# ESP32-C3 register map
Vendor: ESPRESSIF SYSTEMS (SHANGHAI) CO., LTD.; Series: ESP32 C-Series; File version: 19
CPU: RV32IMC r0p0, little endian, no MPU, no FPU, 0 interrupt priority bits
Address unit: 32 bits
Registers are 32-bit, read-write, reset 0x0 unless marked. A register's access mark holds for its fields unless they carry their own. Offsets are from the block's base; [hi:lo] are bit positions; lines under a group give offsets from that group; {n}, {i} and the like mark numbered series.

## SYSTIMER — System Timer
Base 0x60023000
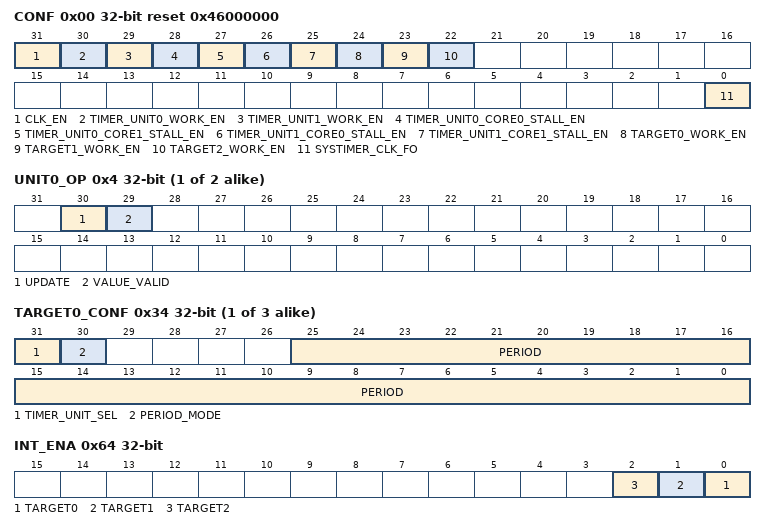
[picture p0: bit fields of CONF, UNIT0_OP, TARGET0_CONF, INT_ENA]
0x00 CONF reset 0x46000000 — SYSTIMER_CONF.
  [31] CLK_EN — register file clk gating
  [30] TIMER_UNIT0_WORK_EN — timer unit0 work enable
  [29] TIMER_UNIT1_WORK_EN — timer unit1 work enable
  [28] TIMER_UNIT0_CORE0_STALL_EN — If timer unit0 is stalled when core0 stalled
  [27] TIMER_UNIT0_CORE1_STALL_EN — If timer unit0 is stalled when core1 stalled
  [26] TIMER_UNIT1_CORE0_STALL_EN — If timer unit1 is stalled when core0 stalled
  [25] TIMER_UNIT1_CORE1_STALL_EN — If timer unit1 is stalled when core1 stalled
  [24] TARGET0_WORK_EN — target0 work enable
  [23] TARGET1_WORK_EN — target1 work enable
  [22] TARGET2_WORK_EN — target2 work enable
  [0] SYSTIMER_CLK_FO — systimer clock force on
{0x4+4i} UNIT{i}_OP (i=0..1) access per field — SYSTIMER_UNIT{i}_OP.
  [30] UPDATE wo — update timer_unit0
  [29] VALUE_VALID ro — reg_timer_unit0_value_valid
{0xC+8i} UNIT{i}LOAD (i=0..1) group — Cluster UNIT{i}LOAD, containing UNIT?_LOAD_HI, UNIT?_LOAD_LO
  0x00 HI — SYSTIMER_UNIT0_LOAD_HI.
    [19:0] LOAD_HI — timer unit0 load high 32 bit
  0x04 LO — SYSTIMER_UNIT0_LOAD_LO.
    [31:0] LOAD_LO — timer unit0 load low 32 bit
{0x1C+8i} TRGT{i} (i=0..2) group — Cluster TRGT{i}, containing TARGET?_HI, TARGET?_LO
  0x00 HI — SYSTIMER_TARGET0_HI.
    [19:0] HI — timer taget0 high 32 bit
  0x04 LO — SYSTIMER_TARGET0_LO.
    [31:0] LO — timer taget0 low 32 bit
{0x34+4i} TARGET{i}_CONF (i=0..2) — SYSTIMER_TARGET{i}_CONF.
  [31] TIMER_UNIT_SEL — select which unit to compare
  [30] PERIOD_MODE — Set target0 to period mode
  [25:0] PERIOD — target0 period
{0x40+8i} UNIT{i}_VALUE (i=0..1) group — Cluster UNIT{i}_VALUE, containing UNIT?_VALUE_HI, UNIT?_VALUE_LO
  0x00 HI ro — SYSTIMER_UNIT0_VALUE_HI.
    [19:0] VALUE_HI — timer read value high 32bit
  0x04 LO ro — SYSTIMER_UNIT0_VALUE_LO.
    [31:0] VALUE_LO — timer read value low 32bit
{0x50+4i} COMP{i}_LOAD (i=0..2) wo — SYSTIMER_COMP{i}_LOAD.
  [0] LOAD — timer comp0 load value
{0x5C+4i} UNIT{i}_LOAD (i=0..1) wo — SYSTIMER_UNIT{i}_LOAD.
  [0] LOAD — timer unit0 load value
0x64 INT_ENA — SYSTIMER_INT_ENA.
  [n] TARGET{n} (n=0..2) — interupt{n} enable
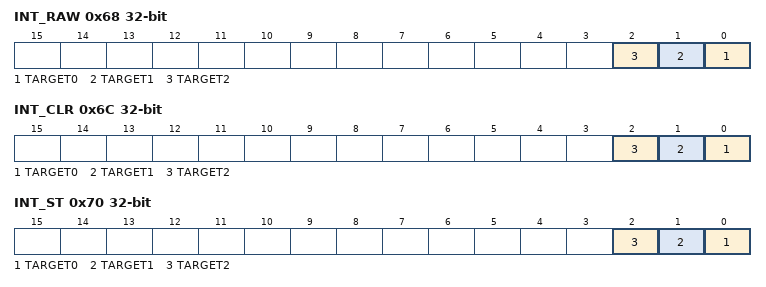
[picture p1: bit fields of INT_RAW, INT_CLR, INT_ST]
0x68 INT_RAW — SYSTIMER_INT_RAW.
  [n] TARGET{n} (n=0..2) — interupt{n} raw
0x6C INT_CLR wo — SYSTIMER_INT_CLR.
  [n] TARGET{n} (n=0..2) write-1-clears — interupt{n} clear
0x70 INT_ST ro — SYSTIMER_INT_ST.
  [n] TARGET{n} (n=0..2) — reg_target{n}_int_st
0xFC DATE — SYSTIMER_DATE.

## TIMG0 — Timer Group 0
Base 0x6001F000
Same registers: TIMG1 0x60020000
{0x0+0x24*i} T{i} (i=0..0) group — Cluster T{i}, containing T?CONFIG, T?LO, T?HI, T?UPDATE, T?ALARMLO, T?ALARMHI, T?LOADLO, T?LOADHI, T?LOAD
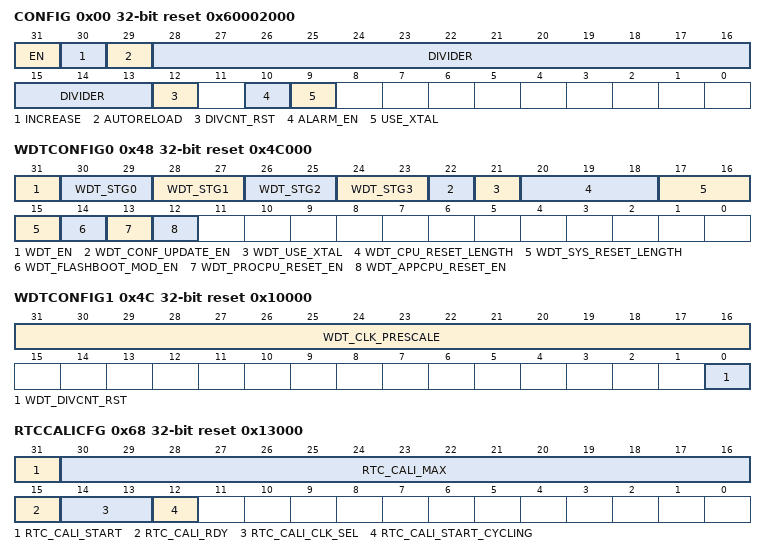
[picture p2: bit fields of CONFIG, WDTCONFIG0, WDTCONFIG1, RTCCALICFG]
  0x00 CONFIG access per field reset 0x60002000 — TIMG_T0CONFIG_REG.
    [31] EN rw — reg_t0_en.
    [30] INCREASE rw — reg_t0_increase.
    [29] AUTORELOAD rw — reg_t0_autoreload.
    [28:13] DIVIDER rw — reg_t0_divider.
    [12] DIVCNT_RST wo — reg_t0_divcnt_rst.
    [10] ALARM_EN rw — reg_t0_alarm_en.
    [9] USE_XTAL rw — reg_t0_use_xtal.
  0x04 LO ro — TIMG_T0LO_REG.
    [31:0] LO — t0_lo
  0x08 HI ro — TIMG_T0HI_REG.
    [21:0] HI — t0_hi
  0x0C UPDATE — TIMG_T0UPDATE_REG.
    [31] UPDATE — t0_update
  0x10 ALARMLO — TIMG_T0ALARMLO_REG.
    [31:0] ALARM_LO — reg_t0_alarm_lo.
  0x14 ALARMHI — TIMG_T0ALARMHI_REG.
    [21:0] ALARM_HI — reg_t0_alarm_hi.
  0x18 LOADLO — TIMG_T0LOADLO_REG.
    [31:0] LOAD_LO — reg_t0_load_lo.
  0x1C LOADHI — TIMG_T0LOADHI_REG.
    [21:0] LOAD_HI — reg_t0_load_hi.
  0x20 LOAD wo — TIMG_T0LOAD_REG.
    [31:0] LOAD — t0_load
0x48 WDTCONFIG0 access per field reset 0x4C000 — TIMG_WDTCONFIG0_REG.
  [31] WDT_EN rw — reg_wdt_en.
  [30-2n:29-2n] WDT_STG{n} rw (n=0..3) — reg_wdt_stg{n}.
  [22] WDT_CONF_UPDATE_EN wo — reg_wdt_conf_update_en.
  [21] WDT_USE_XTAL rw — reg_wdt_use_xtal.
  [20:18] WDT_CPU_RESET_LENGTH rw — reg_wdt_cpu_reset_length.
  [17:15] WDT_SYS_RESET_LENGTH rw — reg_wdt_sys_reset_length.
  [14] WDT_FLASHBOOT_MOD_EN rw — reg_wdt_flashboot_mod_en.
  [13] WDT_PROCPU_RESET_EN rw — reg_wdt_procpu_reset_en.
  [12] WDT_APPCPU_RESET_EN rw — reg_wdt_appcpu_reset_en.
0x4C WDTCONFIG1 access per field reset 0x10000 — TIMG_WDTCONFIG1_REG.
  [31:16] WDT_CLK_PRESCALE rw — reg_wdt_clk_prescale.
  [0] WDT_DIVCNT_RST wo — reg_wdt_divcnt_rst.
{0x48+4i} WDTCONFIG{i} (i=2..5) reset 0x18CBA80 — Watchdog timer stage timeout value
  [31:0] HOLD — reg_wdt_stg0_hold.
0x60 WDTFEED wo — TIMG_WDTFEED_REG.
  [31:0] WDT_FEED
0x64 WDTWPROTECT reset 0x50D83AA1 — TIMG_WDTWPROTECT_REG.
  [31:0] WDT_WKEY — reg_wdt_wkey.
0x68 RTCCALICFG access per field reset 0x13000 — TIMG_RTCCALICFG_REG.
  [31] RTC_CALI_START rw — reg_rtc_cali_start.
  [30:16] RTC_CALI_MAX rw — reg_rtc_cali_max.
  [15] RTC_CALI_RDY ro
  [14:13] RTC_CALI_CLK_SEL rw — reg_rtc_cali_clk_sel.0:rtcslowclock.1:clk_80m.2:xtal_32k
  [12] RTC_CALI_START_CYCLING rw — reg_rtc_cali_start_cycling.
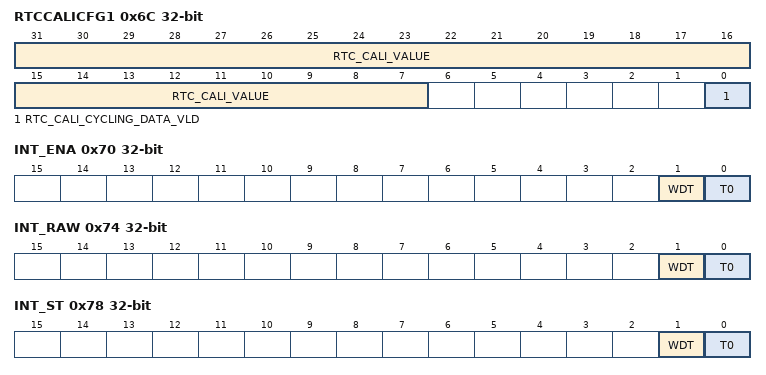
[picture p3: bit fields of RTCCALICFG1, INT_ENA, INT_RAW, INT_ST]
0x6C RTCCALICFG1 ro — TIMG_RTCCALICFG1_REG.
  [31:7] RTC_CALI_VALUE, [0] RTC_CALI_CYCLING_DATA_VLD
0x70 INT_ENA — INT_ENA_TIMG_REG
  [1] WDT — wdt_int_ena
  [n] T{n} (n=0..0) — t{n}_int_ena
0x74 INT_RAW ro — INT_RAW_TIMG_REG
  [1] WDT — wdt_int_raw
  [n] T{n} (n=0..0) — t{n}_int_raw
0x78 INT_ST ro — INT_ST_TIMG_REG
  [1] WDT — wdt_int_st
  [n] T{n} (n=0..0) — t{n}_int_st
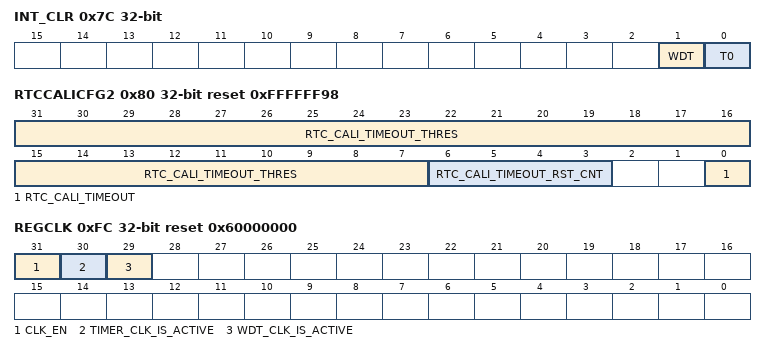
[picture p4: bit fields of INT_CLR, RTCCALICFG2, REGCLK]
0x7C INT_CLR wo — INT_CLR_TIMG_REG
  [1] WDT write-1-clears — wdt_int_clr
  [n] T{n} (n=0..0) write-1-clears — t{n}_int_clr
0x80 RTCCALICFG2 access per field reset 0xFFFFFF98 — TIMG_RTCCALICFG2_REG.
  [31:7] RTC_CALI_TIMEOUT_THRES rw — reg_rtc_cali_timeout_thres.timeoutifcalivaluecountsoverthreshold
  [6:3] RTC_CALI_TIMEOUT_RST_CNT rw — reg_rtc_cali_timeout_rst_cnt.Cyclesthatreleasecalibrationtimeoutreset
  [0] RTC_CALI_TIMEOUT ro — timeoutindicator
0xF8 NTIMG_DATE — TIMG_NTIMG_DATE_REG.
0xFC REGCLK reset 0x60000000 — TIMG_REGCLK_REG.
  [31] CLK_EN — reg_clk_en.
  [30] TIMER_CLK_IS_ACTIVE — reg_timer_clk_is_active.
  [29] WDT_CLK_IS_ACTIVE — reg_wdt_clk_is_active.

## XTS_AES — XTS-AES-128 Flash Encryption
Base 0x600CC000
{0x0+4i} PLAIN_MEM[{i}] (i=0..3) access not given — The memory that stores plaintext
0x40 LINESIZE — XTS-AES line-size register
  [0] LINESIZE — This bit stores the line size parameter. 0: 16Byte, 1: 32Byte.
0x44 DESTINATION — XTS-AES destination register
  [0] DESTINATION — This bit stores the destination. 0: flash(default). 1: reserved.
0x48 PHYSICAL_ADDRESS — XTS-AES physical address register
  [29:0] PHYSICAL_ADDRESS — Those bits stores the physical address. If linesize is 16-byte, the physical address should be aligned of 16 bytes. If linesize is 32-byte, the physical address should be aligned of 32 bytes.
0x4C TRIGGER wo — XTS-AES trigger register
  [0] TRIGGER — Set this bit to start manual encryption calculation
0x50 RELEASE wo — XTS-AES release register
  [0] RELEASE — Set this bit to release the manual encrypted result, after that the result will be visible to spi
0x54 DESTROY wo — XTS-AES destroy register
  [0] DESTROY — Set this bit to destroy XTS-AES result.
0x58 STATE ro — XTS-AES status register
  [1:0] STATE — Those bits shows XTS-AES status. 0=IDLE, 1=WORK, 2=RELEASE, 3=USE. IDLE means that XTS-AES is idle. WORK means that XTS-AES is busy with calculation. RELEASE means the encrypted result is generated but not visible to mspi. USE means that the encrypted result is visible to mspi.
0x5C DATE — XTS-AES version control register
